# TM4C123GH6PM register map
Vendor: Texas Instruments; Series: TM4C; File version: 11073
CPU: CM4 r1p2, little endian, MPU, FPU, 3 interrupt priority bits
Registers are 32-bit, read-write, reset 0x1 unless marked. A register's access mark holds for its fields unless they carry their own. Offsets are from the block's base; [hi:lo] are bit positions.

## QEI0 — Register map for QEI0 peripheral
Base 0x4002C000; register names take the prefix QEI0
Same registers: QEI1 0x4002D000 (register names take the prefix QEI1)
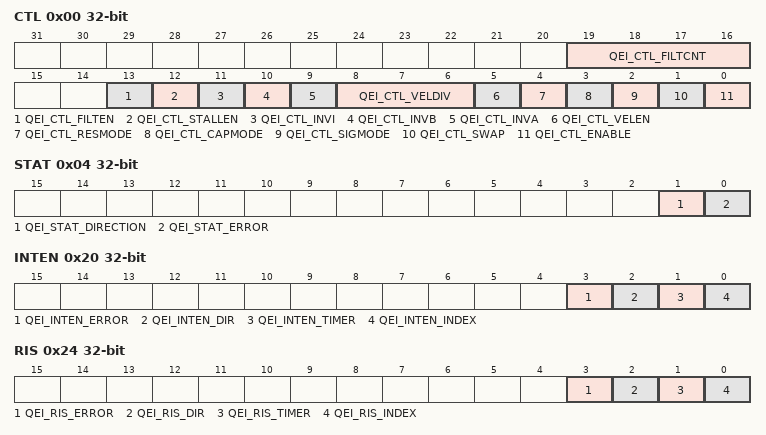
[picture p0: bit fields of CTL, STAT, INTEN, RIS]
0x00 CTL (reset mask 0x0) — QEI Control
  [19:16] QEI_CTL_FILTCNT — Input Filter Prescale Count
  [13] QEI_CTL_FILTEN — Enable Input Filter
  [12] QEI_CTL_STALLEN — Stall QEI
  [11] QEI_CTL_INVI — Invert Index Pulse
  [10] QEI_CTL_INVB — Invert PhB
  [9] QEI_CTL_INVA — Invert PhA
  [8:6] QEI_CTL_VELDIV — Predivide Velocity
    0=QEI clock /1; 1=QEI clock /2; 2=QEI clock /4; 3=QEI clock /8; 4=QEI clock /16; 5=QEI clock /32; 6=QEI clock /64; 7=QEI clock /128
  [5] QEI_CTL_VELEN — Capture Velocity
  [4] QEI_CTL_RESMODE — Reset Mode
  [3] QEI_CTL_CAPMODE — Capture Mode
  [2] QEI_CTL_SIGMODE — Signal Mode
  [1] QEI_CTL_SWAP — Swap Signals
  [0] QEI_CTL_ENABLE — Enable QEI
0x04 STAT (reset mask 0x0) — QEI Status
  [1] QEI_STAT_DIRECTION — Direction of Rotation
  [0] QEI_STAT_ERROR — Error Detected
0x08 POS (reset mask 0x0) — QEI Position
  [31:0] QEI_POS — Current Position Integrator Value
0x0C MAXPOS (reset mask 0x0) — QEI Maximum Position
  [31:0] QEI_MAXPOS — Maximum Position Integrator Value
0x10 LOAD (reset mask 0x0) — QEI Timer Load
  [31:0] QEI_LOAD — Velocity Timer Load Value
0x14 TIME (reset mask 0x0) — QEI Timer
  [31:0] QEI_TIME — Velocity Timer Current Value
0x18 COUNT (reset mask 0x0) — QEI Velocity Counter
  [31:0] QEI_COUNT — Velocity Pulse Count
0x1C SPEED (reset mask 0x0) — QEI Velocity
  [31:0] QEI_SPEED — Velocity
0x20 INTEN (reset mask 0x0) — QEI Interrupt Enable
  [3] QEI_INTEN_ERROR — Phase Error Interrupt Enable
  [2] QEI_INTEN_DIR — Direction Change Interrupt Enable
  [1] QEI_INTEN_TIMER — Timer Expires Interrupt Enable
  [0] QEI_INTEN_INDEX — Index Pulse Detected Interrupt Enable
0x24 RIS (reset mask 0x0) — QEI Raw Interrupt Status
  [3] QEI_RIS_ERROR — Phase Error Detected
  [2] QEI_RIS_DIR — Direction Change Detected
  [1] QEI_RIS_TIMER — Velocity Timer Expired
  [0] QEI_RIS_INDEX — Index Pulse Asserted
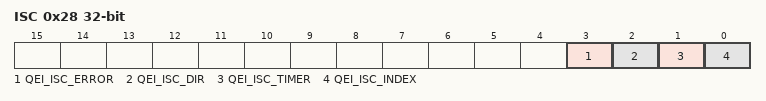
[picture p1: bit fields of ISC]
0x28 ISC (reset mask 0x0) — QEI Interrupt Status and Clear
  [3] QEI_ISC_ERROR — Phase Error Interrupt
  [2] QEI_ISC_DIR — Direction Change Interrupt
  [1] QEI_ISC_TIMER — Velocity Timer Expired Interrupt
  [0] QEI_ISC_INDEX — Index Pulse Interrupt

## COMP — Register map for COMP peripheral
Base 0x4003C000; register names take the prefix COMP
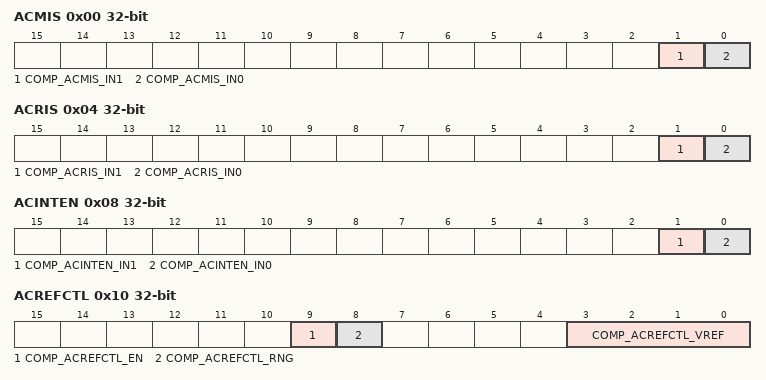
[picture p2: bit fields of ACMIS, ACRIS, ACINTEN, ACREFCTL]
0x00 ACMIS (reset mask 0x0) — Analog Comparator Masked Interrupt Status
  [1] COMP_ACMIS_IN1 — Comparator 1 Masked Interrupt Status
  [0] COMP_ACMIS_IN0 — Comparator 0 Masked Interrupt Status
0x04 ACRIS (reset mask 0x0) — Analog Comparator Raw Interrupt Status
  [1] COMP_ACRIS_IN1 — Comparator 1 Interrupt Status
  [0] COMP_ACRIS_IN0 — Comparator 0 Interrupt Status
0x08 ACINTEN (reset mask 0x0) — Analog Comparator Interrupt Enable
  [1] COMP_ACINTEN_IN1 — Comparator 1 Interrupt Enable
  [0] COMP_ACINTEN_IN0 — Comparator 0 Interrupt Enable
0x10 ACREFCTL (reset mask 0x0) — Analog Comparator Reference Voltage Control
  [9] COMP_ACREFCTL_EN — Resistor Ladder Enable
  [8] COMP_ACREFCTL_RNG — Resistor Ladder Range
  [3:0] COMP_ACREFCTL_VREF — Resistor Ladder Voltage Ref
0x20 ACSTAT0 (reset mask 0x0) — Analog Comparator Status 0
  [1] COMP_ACSTAT0_OVAL — Comparator Output Value
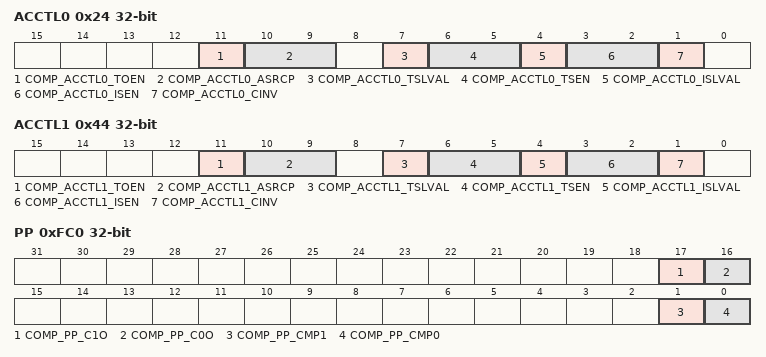
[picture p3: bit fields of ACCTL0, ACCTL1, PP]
0x24 ACCTL0 (reset mask 0x0) — Analog Comparator Control 0
  [11] COMP_ACCTL0_TOEN — Trigger Output Enable
  [10:9] COMP_ACCTL0_ASRCP — Analog Source Positive
    0=COMP_ACCTL0_ASRCP_PIN (Pin value of Cn+); 1=COMP_ACCTL0_ASRCP_PIN0 (Pin value of C0+); 2=COMP_ACCTL0_ASRCP_REF (Internal voltage reference)
  [7] COMP_ACCTL0_TSLVAL — Trigger Sense Level Value
  [6:5] COMP_ACCTL0_TSEN — Trigger Sense
    0=COMP_ACCTL0_TSEN_LEVEL (Level sense, see TSLVAL); 1=COMP_ACCTL0_TSEN_FALL (Falling edge); 2=COMP_ACCTL0_TSEN_RISE (Rising edge); 3=COMP_ACCTL0_TSEN_BOTH (Either edge)
  [4] COMP_ACCTL0_ISLVAL — Interrupt Sense Level Value
  [3:2] COMP_ACCTL0_ISEN — Interrupt Sense
    0=COMP_ACCTL0_ISEN_LEVEL (Level sense, see ISLVAL); 1=COMP_ACCTL0_ISEN_FALL (Falling edge); 2=COMP_ACCTL0_ISEN_RISE (Rising edge); 3=COMP_ACCTL0_ISEN_BOTH (Either edge)
  [1] COMP_ACCTL0_CINV — Comparator Output Invert
0x40 ACSTAT1 (reset mask 0x0) — Analog Comparator Status 1
  [1] COMP_ACSTAT1_OVAL — Comparator Output Value
0x44 ACCTL1 (reset mask 0x0) — Analog Comparator Control 1
  [11] COMP_ACCTL1_TOEN — Trigger Output Enable
  [10:9] COMP_ACCTL1_ASRCP — Analog Source Positive
    0=COMP_ACCTL1_ASRCP_PIN (Pin value of Cn+); 1=COMP_ACCTL1_ASRCP_PIN0 (Pin value of C0+); 2=COMP_ACCTL1_ASRCP_REF (Internal voltage reference (VIREF))
  [7] COMP_ACCTL1_TSLVAL — Trigger Sense Level Value
  [6:5] COMP_ACCTL1_TSEN — Trigger Sense
    0=COMP_ACCTL1_TSEN_LEVEL (Level sense, see TSLVAL); 1=COMP_ACCTL1_TSEN_FALL (Falling edge); 2=COMP_ACCTL1_TSEN_RISE (Rising edge); 3=COMP_ACCTL1_TSEN_BOTH (Either edge)
  [4] COMP_ACCTL1_ISLVAL — Interrupt Sense Level Value
  [3:2] COMP_ACCTL1_ISEN — Interrupt Sense
    0=COMP_ACCTL1_ISEN_LEVEL (Level sense, see ISLVAL); 1=COMP_ACCTL1_ISEN_FALL (Falling edge); 2=COMP_ACCTL1_ISEN_RISE (Rising edge); 3=COMP_ACCTL1_ISEN_BOTH (Either edge)
  [1] COMP_ACCTL1_CINV — Comparator Output Invert
0xFC0 PP (reset mask 0x0) — Analog Comparator Peripheral Properties
  [17] COMP_PP_C1O — Comparator Output 1 Present
  [16] COMP_PP_C0O — Comparator Output 0 Present
  [1] COMP_PP_CMP1 — Comparator 1 Present
  [0] COMP_PP_CMP0 — Comparator 0 Present
